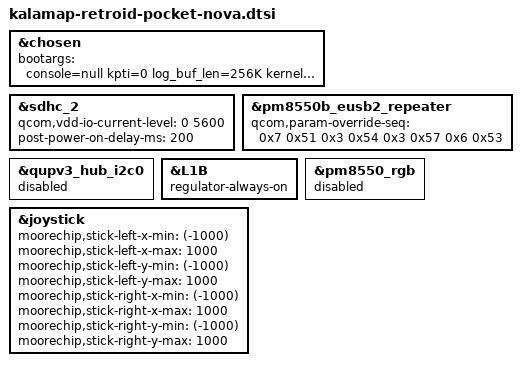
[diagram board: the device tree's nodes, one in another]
#include "kalamap-moorechip-common.dtsi"
#include "joystick/kalamap-moorechip-joystick-mappable.dtsi"
#include "joystick/kalamap-moorechip-joystick-nintendo.dtsi"
#include "leds/kalamap-moorechip-leds-htr3212.dtsi"
#include "vibrator/kalamap-moorechip-vibrator-lra.dtsi"

&chosen {
	bootargs = "console=null kpti=0 log_buf_len=256K kernel.panic_on_rcu_stall=1 service_locator.enable=1 msm_rtb.filter=0x237 rcupdate.rcu_expedited=1 rcu_nocbs=0-7 ftrace_dump_on_oops swiotlb=noforce loop.max_part=7 fw_devlink.strict=1 allow_mismatched_32bit_el0 cpufreq.default_governor=performance printk.console_no_auto_verbose=1 kasan=off sysctl.kernel.sched_pelt_multiplier=4 can.stats_timer=0 pcie_ports=compat irqaffinity=0-2 disable_dma32=on no-steal-acc cgroup.memory=nokmem,nosocket slub_debug=- msm_drm.moorechip_dsi_display0=qcom,mdss_dsi_xingxing_4_5_1280_960_cmd:";
};

&sdhc_2 {
	qcom,vdd-io-current-level = <0 5600>;
	post-power-on-delay-ms = <200>;
};

&pm8550b_eusb2_repeater {
	qcom,param-override-seq =
		/* <value reg_offset> */
		/* Adjust HS trasmit amplitude */
		<0x7 0x51
		/* Squelch detection threshold */
		 0x3 0x54
		/* Tx pre-emphasis tuning */
		 0x3 0x57
		/* HS disconnect threshold */
		 0x6 0x53>;
};

&qupv3_hub_i2c0 {
	status = "disabled";
};

// TODO: Unknown, but removal of this breaks booting recovery.
&L1B {
	regulator-always-on;
};

&pm8550_rgb {
	status = "disabled";
};

&joystick {
        moorechip,stick-left-x-min = <(-1000)>;
        moorechip,stick-left-x-max = <1000>;
        moorechip,stick-left-y-min = <(-1000)>;
        moorechip,stick-left-y-max = <1000>;
        moorechip,stick-right-x-min = <(-1000)>;
        moorechip,stick-right-x-max = <1000>;
        moorechip,stick-right-y-min = <(-1000)>;
        moorechip,stick-right-y-max = <1000>;
};
